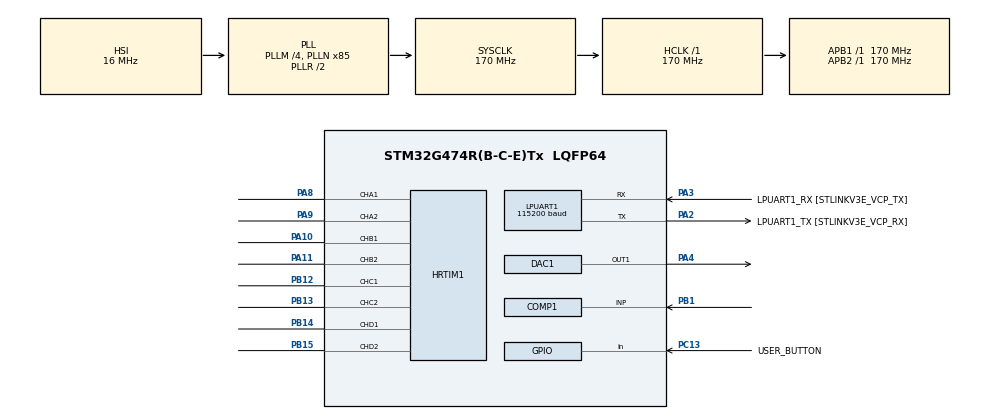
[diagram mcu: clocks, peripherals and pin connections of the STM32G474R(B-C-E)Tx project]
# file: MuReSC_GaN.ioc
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COMP1.Hysteresis=COMP_HYSTERESIS_10MV
COMP1.TriggerMode=COMP_TRIGGERMODE_IT_RISING_FALLING
HRTIM1.CompareUnit1-Output_TA1TA2=HRTIM_COMPAREUNIT_1
HRTIM1.CompareUnit1-Output_TB1TB2=__NULL
HRTIM1.CompareUnit1-Output_TC1TC2=HRTIM_COMPAREUNIT_1
HRTIM1.CompareUnit1-Output_TD1TD2=__NULL
HRTIM1.CompareUnit2-Output_TA1TA2=HRTIM_COMPAREUNIT_2
HRTIM1.CompareUnit2-Output_TB1TB2=HRTIM_COMPAREUNIT_2
HRTIM1.CompareUnit2-Output_TC1TC2=HRTIM_COMPAREUNIT_2
HRTIM1.CompareUnit2-Output_TD1TD2=HRTIM_COMPAREUNIT_2
HRTIM1.CompareValue1-Output_TA1TA2=4352/3
HRTIM1.CompareValue1-Output_TC1TC2=4352/10
HRTIM1.CompareValue2-Output_TA1TA2=4352*2/3
HRTIM1.CompareValue2-Output_TB1TB2=4352
HRTIM1.CompareValue2-Output_TC1TC2=4352*2/10
HRTIM1.CompareValue2-Output_TD1TD2=4352*3/20
HRTIM1.Deadtimeconfig-Output_TD1TD2=__NULL
HRTIM1.NumberResetSource1-Output_TA1TA2=1
HRTIM1.NumberResetSource1-Output_TB1TB2=1
HRTIM1.NumberResetSource1-Output_TC1TC2=1
HRTIM1.NumberResetSource1-Output_TD1TD2=1
HRTIM1.NumberResetSource2_TA=1
HRTIM1.NumberResetSource2_TB=1
HRTIM1.NumberResetSource2_TC=1
HRTIM1.NumberResetSource2_TD=1
HRTIM1.NumberSetSource1-Output_TA1TA2=1
HRTIM1.NumberSetSource1-Output_TB1TB2=1
HRTIM1.NumberSetSource1-Output_TC1TC2=1
HRTIM1.NumberSetSource1-Output_TD1TD2=1
HRTIM1.NumberSetSource2_TA=1
HRTIM1.NumberSetSource2_TB=1
HRTIM1.NumberSetSource2_TC=1
HRTIM1.NumberSetSource2_TD=1
HRTIM1.Periode_TA=4352
HRTIM1.Periode_TB=4352
HRTIM1.Periode_TC=4352
HRTIM1.Periode_TD=4352
HRTIM1.Polarity1-Output_TA1TA2=HRTIM_OUTPUTPOLARITY_LOW
HRTIM1.Polarity1-Output_TB1TB2=HRTIM_OUTPUTPOLARITY_LOW
HRTIM1.Polarity1-Output_TC1TC2=HRTIM_OUTPUTPOLARITY_LOW
HRTIM1.Polarity1-Output_TD1TD2=HRTIM_OUTPUTPOLARITY_LOW
HRTIM1.Polarity2-Output_TA1TA2=HRTIM_OUTPUTPOLARITY_HIGH
HRTIM1.Polarity2-Output_TB1TB2=HRTIM_OUTPUTPOLARITY_HIGH
HRTIM1.Polarity2-Output_TC1TC2=HRTIM_OUTPUTPOLARITY_HIGH
HRTIM1.Polarity2-Output_TD1TD2=HRTIM_OUTPUTPOLARITY_HIGH
HRTIM1.ResetOutput1_Source1-Output_TA1TA2=HRTIM_OUTPUTRESET_TIMCMP2
HRTIM1.ResetOutput1_Source1-Output_TB1TB2=HRTIM_OUTPUTRESET_TIMCMP2
HRTIM1.ResetOutput1_Source1-Output_TC1TC2=HRTIM_OUTPUTRESET_TIMCMP2
HRTIM1.ResetOutput1_Source1-Output_TD1TD2=HRTIM_OUTPUTRESET_TIMCMP2
HRTIM1.ResetOutput2_Source1-Output_TA1TA2=HRTIM_OUTPUTRESET_TIMCMP2
HRTIM1.ResetOutput2_Source1-Output_TB1TB2=HRTIM_OUTPUTRESET_TIMCMP2
HRTIM1.ResetOutput2_Source1-Output_TC1TC2=HRTIM_OUTPUTRESET_TIMCMP2
HRTIM1.ResetOutput2_Source1-Output_TD1TD2=HRTIM_OUTPUTRESET_TIMCMP2
HRTIM1.SetOutput1_Source1-Output_TA1TA2=HRTIM_OUTPUTSET_TIMCMP1
HRTIM1.SetOutput1_Source1-Output_TB1TB2=HRTIM_OUTPUTSET_TIMPER
HRTIM1.SetOutput1_Source1-Output_TC1TC2=HRTIM_OUTPUTSET_TIMCMP1
HRTIM1.SetOutput1_Source1-Output_TD1TD2=HRTIM_OUTPUTSET_TIMPER
HRTIM1.SetOutput2_Source1-Output_TA1TA2=HRTIM_OUTPUTSET_TIMCMP1
HRTIM1.SetOutput2_Source1-Output_TB1TB2=HRTIM_OUTPUTSET_TIMPER
HRTIM1.SetOutput2_Source1-Output_TC1TC2=HRTIM_OUTPUTSET_TIMCMP1
HRTIM1.SetOutput2_Source1-Output_TD1TD2=HRTIM_OUTPUTSET_TIMPER
LPUART1.BaudRate=115200
LPUART1.WordLength=UART_WORDLENGTH_8B
Mcu.Family=STM32G4
Mcu.Name=STM32G474R(B-C-E)Tx
Mcu.Package=LQFP64
NVIC.COMP1_2_3_IRQn=true\:0\:0\:false\:false\:true\:false\:true\:true
NVIC.LPUART1_IRQn=true\:0\:0\:false\:false\:true\:true\:true\:true
NVIC.PVD_PVM_IRQn=true\:0\:0\:false\:false\:true\:true\:true\:true
NVIC.PriorityGroup=NVIC_PRIORITYGROUP_4
PA10.GPIO_PuPd=GPIO_PULLUP
PA10.Mode=Output_TB1TB2
PA10.Signal=HRTIM1_CHB1
PA11.GPIO_PuPd=GPIO_PULLDOWN
PA11.Mode=Output_TB1TB2
PA11.Signal=HRTIM1_CHB2
PA13.GPIO_Label=T_SWDIO
PA13.Mode=Serial_Wire
PA13.Signal=SYS_JTMS-SWDIO
PA14.GPIO_Label=T_SWCLK
PA14.Mode=Serial_Wire
PA14.Signal=SYS_JTCK-SWCLK
PA2.GPIO_Label=LPUART1_TX [STLINKV3E_VCP_RX]
PA2.Mode=Asynchronous
PA2.Signal=LPUART1_TX
PA3.GPIO_Label=LPUART1_RX [STLINKV3E_VCP_TX]
PA3.Mode=Asynchronous
PA3.Signal=LPUART1_RX
PA4.Signal=COMP_DAC11_group
PA8.GPIO_PuPd=GPIO_PULLUP
PA8.Mode=Output_TA1TA2
PA8.Signal=HRTIM1_CHA1
PA9.GPIO_PuPd=GPIO_PULLDOWN
PA9.Mode=Output_TA1TA2
PA9.Signal=HRTIM1_CHA2
PB1.Mode=INP
PB1.Signal=COMP1_INP
PB12.GPIO_PuPd=GPIO_PULLUP
PB12.Mode=Output_TC1TC2
PB12.Signal=HRTIM1_CHC1
PB13.GPIO_PuPd=GPIO_PULLDOWN
PB13.Mode=Output_TC1TC2
PB13.Signal=HRTIM1_CHC2
PB14.GPIO_PuPd=GPIO_PULLUP
PB14.Mode=Output_TD1TD2
PB14.Signal=HRTIM1_CHD1
PB15.GPIO_PuPd=GPIO_PULLDOWN
PB15.Mode=Output_TD1TD2
PB15.Signal=HRTIM1_CHD2
PC13.GPIO_Label=USER_BUTTON
PC13.Signal=GPIO_Input
PC14-OSC32_IN.Mode=LSE-External-Oscillator
PC14-OSC32_IN.Signal=RCC_OSC32_IN
PC15-OSC32_OUT.Mode=LSE-External-Oscillator
PC15-OSC32_OUT.Signal=RCC_OSC32_OUT
PF0-OSC_IN.Mode=HSE-External-Oscillator
PF0-OSC_IN.Signal=RCC_OSC_IN
PF1-OSC_OUT.Mode=HSE-External-Oscillator
PF1-OSC_OUT.Signal=RCC_OSC_OUT
ProjectManager.HeapSize=0x200
ProjectManager.StackSize=0x400
ProjectManager.TargetToolchain=STM32CubeIDE
RCC.ADC12Freq_Value=170000000
RCC.ADC345Freq_Value=170000000
RCC.AHBFreq_Value=170000000
RCC.APB1Freq_Value=170000000
RCC.APB1TimFreq_Value=170000000
RCC.APB2Freq_Value=170000000
RCC.APB2TimFreq_Value=170000000
RCC.CortexFreq_Value=170000000
RCC.EXTERNAL_CLOCK_VALUE=12288000
RCC.HCLKFreq_Value=170000000
RCC.HSE_VALUE=24000000
RCC.HSI48_VALUE=48000000
RCC.HSI_VALUE=16000000
RCC.PLLM=RCC_PLLM_DIV4
RCC.PLLN=85
RCC.RTCClockSelection=RCC_RTCCLKSOURCE_LSE
RCC.SYSCLKFreq_VALUE=170000000
RCC.SYSCLKSource=RCC_SYSCLKSOURCE_PLLCLK
RCC.USBFreq_Value=170000000
RCC.VCOOutputFreq_Value=340000000
SH.COMP_DAC11_group.0=DAC1_OUT1,DAC_OUT1_ExtAndInt
VP_COMP1_VS_DAC1OUT1.Mode=INM_DAC1OUT1
VP_SYS_VS_DBSignals.Mode=DisableDeadBatterySignals
board=NUCLEO-G474RE

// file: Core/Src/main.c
/* USER CODE BEGIN Header */

/*
 * This file is part of the PCBs project (https://github.com/gremirarunico/PCBs).
 * Copyright (c) 2024 Marco Guerrini.
 *
 * This program is free software: you can redistribute it and/or modify
 * it under the terms of the GNU General Public License as published by
 * the Free Software Foundation, version 3.
 *
 * This program is distributed in the hope that it will be useful, but
 * WITHOUT ANY WARRANTY; without even the implied warranty of
 * MERCHANTABILITY or FITNESS FOR A PARTICULAR PURPOSE. See the GNU
 * General Public License for more details.
 *
 * You should have received a copy of the GNU General Public License
 * along with this program. If not, see <http://www.gnu.org/licenses/>.
 */

#include <stdio.h>
#include <stdbool.h>
#include <serial_parser.h>
#include "application.h"
/* USER CODE END Header */
#include "main.h"

COMP_HandleTypeDef hcomp1;

DAC_HandleTypeDef hdac1;

HRTIM_HandleTypeDef hhrtim1;

UART_HandleTypeDef hlpuart1;

void SystemClock_Config(void);
static void MX_GPIO_Init(void);
static void MX_LPUART1_UART_Init(void);
static void MX_HRTIM1_Init(void);
static void MX_DAC1_Init(void);
static void MX_COMP1_Init(void);

int main(void)
{

  /* MCU Configuration--------------------------------------------------------*/

  /* Reset of all peripherals, Initializes the Flash interface and the Systick. */
  HAL_Init();

  /* Configure the system clock */
  SystemClock_Config();

  /* Initialize all configured peripherals */
  MX_GPIO_Init();
  MX_LPUART1_UART_Init();
  MX_HRTIM1_Init();
  MX_DAC1_Init();
  MX_COMP1_Init();
  /* USER CODE BEGIN 2 */
  setup();

	while (1) {
		loop();
	}
	/* USER CODE BEGIN 3 */
	/* USER CODE END 3 */

  /* USER CODE END 2 */

  /* Infinite loop */

}

void SystemClock_Config(void)
{
  RCC_OscInitTypeDef RCC_OscInitStruct = {0};
  RCC_ClkInitTypeDef RCC_ClkInitStruct = {0};

  /** Configure the main internal regulator output voltage
  */
  HAL_PWREx_ControlVoltageScaling(PWR_REGULATOR_VOLTAGE_SCALE1_BOOST);

  /** Initializes the RCC Oscillators according to the specified parameters
  * in the RCC_OscInitTypeDef structure.
  */
  RCC_OscInitStruct.OscillatorType = RCC_OSCILLATORTYPE_HSI;
  RCC_OscInitStruct.HSIState = RCC_HSI_ON;
  RCC_OscInitStruct.HSICalibrationValue = RCC_HSICALIBRATION_DEFAULT;
  RCC_OscInitStruct.PLL.PLLState = RCC_PLL_ON;
  RCC_OscInitStruct.PLL.PLLSource = RCC_PLLSOURCE_HSI;
  RCC_OscInitStruct.PLL.PLLM = RCC_PLLM_DIV4;
  RCC_OscInitStruct.PLL.PLLN = 85;
  RCC_OscInitStruct.PLL.PLLP = RCC_PLLP_DIV2;
  RCC_OscInitStruct.PLL.PLLQ = RCC_PLLQ_DIV2;
  RCC_OscInitStruct.PLL.PLLR = RCC_PLLR_DIV2;
  if (HAL_RCC_OscConfig(&RCC_OscInitStruct) != HAL_OK)
  {
    Error_Handler();
  }

  /** Initializes the CPU, AHB and APB buses clocks
  */
  RCC_ClkInitStruct.ClockType = RCC_CLOCKTYPE_HCLK|RCC_CLOCKTYPE_SYSCLK
                              |RCC_CLOCKTYPE_PCLK1|RCC_CLOCKTYPE_PCLK2;
  RCC_ClkInitStruct.SYSCLKSource = RCC_SYSCLKSOURCE_PLLCLK;
  RCC_ClkInitStruct.AHBCLKDivider = RCC_SYSCLK_DIV1;
  RCC_ClkInitStruct.APB1CLKDivider = RCC_HCLK_DIV1;
  RCC_ClkInitStruct.APB2CLKDivider = RCC_HCLK_DIV1;

  if (HAL_RCC_ClockConfig(&RCC_ClkInitStruct, FLASH_LATENCY_4) != HAL_OK)
  {
    Error_Handler();
  }
}

static void MX_COMP1_Init(void)
{

  hcomp1.Instance = COMP1;
  hcomp1.Init.InputPlus = COMP_INPUT_PLUS_IO2;
  hcomp1.Init.InputMinus = COMP_INPUT_MINUS_DAC1_CH1;
  hcomp1.Init.OutputPol = COMP_OUTPUTPOL_NONINVERTED;
  hcomp1.Init.Hysteresis = COMP_HYSTERESIS_10MV;
  hcomp1.Init.BlankingSrce = COMP_BLANKINGSRC_NONE;
  hcomp1.Init.TriggerMode = COMP_TRIGGERMODE_IT_RISING_FALLING;
  if (HAL_COMP_Init(&hcomp1) != HAL_OK)
  {
    Error_Handler();
  }

}

static void MX_DAC1_Init(void)
{

  DAC_ChannelConfTypeDef sConfig = {0};

  /** DAC Initialization
  */
  hdac1.Instance = DAC1;
  if (HAL_DAC_Init(&hdac1) != HAL_OK)
  {
    Error_Handler();
  }

  /** DAC channel OUT1 config
  */
  sConfig.DAC_HighFrequency = DAC_HIGH_FREQUENCY_INTERFACE_MODE_AUTOMATIC;
  sConfig.DAC_DMADoubleDataMode = DISABLE;
  sConfig.DAC_SignedFormat = DISABLE;
  sConfig.DAC_SampleAndHold = DAC_SAMPLEANDHOLD_DISABLE;
  sConfig.DAC_Trigger = DAC_TRIGGER_NONE;
  sConfig.DAC_Trigger2 = DAC_TRIGGER_NONE;
  sConfig.DAC_OutputBuffer = DAC_OUTPUTBUFFER_ENABLE;
  sConfig.DAC_ConnectOnChipPeripheral = DAC_CHIPCONNECT_BOTH;
  sConfig.DAC_UserTrimming = DAC_TRIMMING_FACTORY;
  if (HAL_DAC_ConfigChannel(&hdac1, &sConfig, DAC_CHANNEL_1) != HAL_OK)
  {
    Error_Handler();
  }

}

static void MX_HRTIM1_Init(void)
{

  HRTIM_TimeBaseCfgTypeDef pTimeBaseCfg = {0};
  HRTIM_TimerCtlTypeDef pTimerCtl = {0};
  HRTIM_TimerCfgTypeDef pTimerCfg = {0};
  HRTIM_CompareCfgTypeDef pCompareCfg = {0};
  HRTIM_OutputCfgTypeDef pOutputCfg = {0};

  hhrtim1.Instance = HRTIM1;
  hhrtim1.Init.HRTIMInterruptResquests = HRTIM_IT_NONE;
  hhrtim1.Init.SyncOptions = HRTIM_SYNCOPTION_NONE;
  if (HAL_HRTIM_Init(&hhrtim1) != HAL_OK)
  {
    Error_Handler();
  }
  if (HAL_HRTIM_DLLCalibrationStart(&hhrtim1, HRTIM_CALIBRATIONRATE_3) != HAL_OK)
  {
    Error_Handler();
  }
  if (HAL_HRTIM_PollForDLLCalibration(&hhrtim1, 10) != HAL_OK)
  {
    Error_Handler();
  }
  pTimeBaseCfg.Period = 4352;
  pTimeBaseCfg.RepetitionCounter = 0x00;
  pTimeBaseCfg.PrescalerRatio = HRTIM_PRESCALERRATIO_MUL32;
  pTimeBaseCfg.Mode = HRTIM_MODE_CONTINUOUS;
  if (HAL_HRTIM_TimeBaseConfig(&hhrtim1, HRTIM_TIMERINDEX_TIMER_A, &pTimeBaseCfg) != HAL_OK)
  {
    Error_Handler();
  }
  pTimerCtl.UpDownMode = HRTIM_TIMERUPDOWNMODE_UP;
  pTimerCtl.TrigHalf = HRTIM_TIMERTRIGHALF_DISABLED;
  pTimerCtl.GreaterCMP1 = HRTIM_TIMERGTCMP1_EQUAL;
  pTimerCtl.DualChannelDacEnable = HRTIM_TIMER_DCDE_DISABLED;
  if (HAL_HRTIM_WaveformTimerControl(&hhrtim1, HRTIM_TIMERINDEX_TIMER_A, &pTimerCtl) != HAL_OK)
  {
    Error_Handler();
  }
  pTimerCfg.InterruptRequests = HRTIM_TIM_IT_NONE;
  pTimerCfg.DMARequests = HRTIM_TIM_DMA_NONE;
  pTimerCfg.DMASrcAddress = 0x0000;
  pTimerCfg.DMADstAddress = 0x0000;
  pTimerCfg.DMASize = 0x1;
  pTimerCfg.HalfModeEnable = HRTIM_HALFMODE_DISABLED;
  pTimerCfg.InterleavedMode = HRTIM_INTERLEAVED_MODE_DISABLED;
  pTimerCfg.StartOnSync = HRTIM_SYNCSTART_DISABLED;
  pTimerCfg.ResetOnSync = HRTIM_SYNCRESET_DISABLED;
  pTimerCfg.DACSynchro = HRTIM_DACSYNC_NONE;
  pTimerCfg.PreloadEnable = HRTIM_PRELOAD_DISABLED;
  pTimerCfg.UpdateGating = HRTIM_UPDATEGATING_INDEPENDENT;
  pTimerCfg.BurstMode = HRTIM_TIMERBURSTMODE_MAINTAINCLOCK;
  pTimerCfg.RepetitionUpdate = HRTIM_UPDATEONREPETITION_DISABLED;
  pTimerCfg.PushPull = HRTIM_TIMPUSHPULLMODE_DISABLED;
  pTimerCfg.FaultEnable = HRTIM_TIMFAULTENABLE_NONE;
  pTimerCfg.FaultLock = HRTIM_TIMFAULTLOCK_READWRITE;
  pTimerCfg.DeadTimeInsertion = HRTIM_TIMDEADTIMEINSERTION_DISABLED;
  pTimerCfg.DelayedProtectionMode = HRTIM_TIMER_A_B_C_DELAYEDPROTECTION_DISABLED;
  pTimerCfg.UpdateTrigger = HRTIM_TIMUPDATETRIGGER_NONE;
  pTimerCfg.ResetTrigger = HRTIM_TIMRESETTRIGGER_NONE;
  pTimerCfg.ResetUpdate = HRTIM_TIMUPDATEONRESET_DISABLED;
  pTimerCfg.ReSyncUpdate = HRTIM_TIMERESYNC_UPDATE_UNCONDITIONAL;
  if (HAL_HRTIM_WaveformTimerConfig(&hhrtim1, HRTIM_TIMERINDEX_TIMER_A, &pTimerCfg) != HAL_OK)
  {
    Error_Handler();
  }
  if (HAL_HRTIM_WaveformTimerConfig(&hhrtim1, HRTIM_TIMERINDEX_TIMER_B, &pTimerCfg) != HAL_OK)
  {
    Error_Handler();
  }
  if (HAL_HRTIM_WaveformTimerConfig(&hhrtim1, HRTIM_TIMERINDEX_TIMER_C, &pTimerCfg) != HAL_OK)
  {
    Error_Handler();
  }
  pTimerCfg.DelayedProtectionMode = HRTIM_TIMER_D_E_DELAYEDPROTECTION_DISABLED;
  if (HAL_HRTIM_WaveformTimerConfig(&hhrtim1, HRTIM_TIMERINDEX_TIMER_D, &pTimerCfg) != HAL_OK)
  {
    Error_Handler();
  }
  pCompareCfg.CompareValue = 4352/3;
  if (HAL_HRTIM_WaveformCompareConfig(&hhrtim1, HRTIM_TIMERINDEX_TIMER_A, HRTIM_COMPAREUNIT_1, &pCompareCfg) != HAL_OK)
  {
    Error_Handler();
  }
  pCompareCfg.CompareValue = 4352*2/3;
  pCompareCfg.AutoDelayedMode = HRTIM_AUTODELAYEDMODE_REGULAR;
  pCompareCfg.AutoDelayedTimeout = 0x0000;

  if (HAL_HRTIM_WaveformCompareConfig(&hhrtim1, HRTIM_TIMERINDEX_TIMER_A, HRTIM_COMPAREUNIT_2, &pCompareCfg) != HAL_OK)
  {
    Error_Handler();
  }
  pOutputCfg.Polarity = HRTIM_OUTPUTPOLARITY_LOW;
  pOutputCfg.SetSource = HRTIM_OUTPUTSET_TIMCMP1;
  pOutputCfg.ResetSource = HRTIM_OUTPUTRESET_TIMCMP2;
  pOutputCfg.IdleMode = HRTIM_OUTPUTIDLEMODE_NONE;
  pOutputCfg.IdleLevel = HRTIM_OUTPUTIDLELEVEL_INACTIVE;
  pOutputCfg.FaultLevel = HRTIM_OUTPUTFAULTLEVEL_NONE;
  pOutputCfg.ChopperModeEnable = HRTIM_OUTPUTCHOPPERMODE_DISABLED;
  pOutputCfg.BurstModeEntryDelayed = HRTIM_OUTPUTBURSTMODEENTRY_REGULAR;
  if (HAL_HRTIM_WaveformOutputConfig(&hhrtim1, HRTIM_TIMERINDEX_TIMER_A, HRTIM_OUTPUT_TA1, &pOutputCfg) != HAL_OK)
  {
    Error_Handler();
  }
  pOutputCfg.SetSource = HRTIM_OUTPUTSET_TIMPER;
  if (HAL_HRTIM_WaveformOutputConfig(&hhrtim1, HRTIM_TIMERINDEX_TIMER_B, HRTIM_OUTPUT_TB1, &pOutputCfg) != HAL_OK)
  {
    Error_Handler();
  }
  pOutputCfg.SetSource = HRTIM_OUTPUTSET_TIMCMP1;
  if (HAL_HRTIM_WaveformOutputConfig(&hhrtim1, HRTIM_TIMERINDEX_TIMER_C, HRTIM_OUTPUT_TC1, &pOutputCfg) != HAL_OK)
  {
    Error_Handler();
  }
  pOutputCfg.SetSource = HRTIM_OUTPUTSET_TIMPER;
  if (HAL_HRTIM_WaveformOutputConfig(&hhrtim1, HRTIM_TIMERINDEX_TIMER_D, HRTIM_OUTPUT_TD1, &pOutputCfg) != HAL_OK)
  {
    Error_Handler();
  }
  pOutputCfg.Polarity = HRTIM_OUTPUTPOLARITY_HIGH;
  pOutputCfg.SetSource = HRTIM_OUTPUTSET_TIMCMP1;
  if (HAL_HRTIM_WaveformOutputConfig(&hhrtim1, HRTIM_TIMERINDEX_TIMER_A, HRTIM_OUTPUT_TA2, &pOutputCfg) != HAL_OK)
  {
    Error_Handler();
  }
  pOutputCfg.SetSource = HRTIM_OUTPUTSET_TIMPER;
  if (HAL_HRTIM_WaveformOutputConfig(&hhrtim1, HRTIM_TIMERINDEX_TIMER_B, HRTIM_OUTPUT_TB2, &pOutputCfg) != HAL_OK)
  {
    Error_Handler();
  }
  pOutputCfg.SetSource = HRTIM_OUTPUTSET_TIMCMP1;
  if (HAL_HRTIM_WaveformOutputConfig(&hhrtim1, HRTIM_TIMERINDEX_TIMER_C, HRTIM_OUTPUT_TC2, &pOutputCfg) != HAL_OK)
  {
    Error_Handler();
  }
  pOutputCfg.SetSource = HRTIM_OUTPUTSET_TIMPER;
  if (HAL_HRTIM_WaveformOutputConfig(&hhrtim1, HRTIM_TIMERINDEX_TIMER_D, HRTIM_OUTPUT_TD2, &pOutputCfg) != HAL_OK)
  {
    Error_Handler();
  }
  if (HAL_HRTIM_TimeBaseConfig(&hhrtim1, HRTIM_TIMERINDEX_TIMER_B, &pTimeBaseCfg) != HAL_OK)
  {
    Error_Handler();
  }
  if (HAL_HRTIM_WaveformTimerControl(&hhrtim1, HRTIM_TIMERINDEX_TIMER_B, &pTimerCtl) != HAL_OK)
  {
    Error_Handler();
  }
  pCompareCfg.CompareValue = 4352;

  if (HAL_HRTIM_WaveformCompareConfig(&hhrtim1, HRTIM_TIMERINDEX_TIMER_B, HRTIM_COMPAREUNIT_2, &pCompareCfg) != HAL_OK)
  {
    Error_Handler();
  }
  if (HAL_HRTIM_TimeBaseConfig(&hhrtim1, HRTIM_TIMERINDEX_TIMER_C, &pTimeBaseCfg) != HAL_OK)
  {
    Error_Handler();
  }
  if (HAL_HRTIM_WaveformTimerControl(&hhrtim1, HRTIM_TIMERINDEX_TIMER_C, &pTimerCtl) != HAL_OK)
  {
    Error_Handler();
  }
  pCompareCfg.CompareValue = 4352/10;
  if (HAL_HRTIM_WaveformCompareConfig(&hhrtim1, HRTIM_TIMERINDEX_TIMER_C, HRTIM_COMPAREUNIT_1, &pCompareCfg) != HAL_OK)
  {
    Error_Handler();
  }
  pCompareCfg.CompareValue = 4352*2/10;

  if (HAL_HRTIM_WaveformCompareConfig(&hhrtim1, HRTIM_TIMERINDEX_TIMER_C, HRTIM_COMPAREUNIT_2, &pCompareCfg) != HAL_OK)
  {
    Error_Handler();
  }
  if (HAL_HRTIM_TimeBaseConfig(&hhrtim1, HRTIM_TIMERINDEX_TIMER_D, &pTimeBaseCfg) != HAL_OK)
  {
    Error_Handler();
  }
  if (HAL_HRTIM_WaveformTimerControl(&hhrtim1, HRTIM_TIMERINDEX_TIMER_D, &pTimerCtl) != HAL_OK)
  {
    Error_Handler();
  }
  pCompareCfg.CompareValue = 4352*3/20;

  if (HAL_HRTIM_WaveformCompareConfig(&hhrtim1, HRTIM_TIMERINDEX_TIMER_D, HRTIM_COMPAREUNIT_2, &pCompareCfg) != HAL_OK)
  {
    Error_Handler();
  }
  HAL_HRTIM_MspPostInit(&hhrtim1);

}

static void MX_LPUART1_UART_Init(void)
{

  hlpuart1.Instance = LPUART1;
  hlpuart1.Init.BaudRate = 115200;
  hlpuart1.Init.WordLength = UART_WORDLENGTH_8B;
  hlpuart1.Init.StopBits = UART_STOPBITS_1;
  hlpuart1.Init.Parity = UART_PARITY_NONE;
  hlpuart1.Init.Mode = UART_MODE_TX_RX;
  hlpuart1.Init.HwFlowCtl = UART_HWCONTROL_NONE;
  hlpuart1.Init.OneBitSampling = UART_ONE_BIT_SAMPLE_DISABLE;
  hlpuart1.Init.ClockPrescaler = UART_PRESCALER_DIV1;
  hlpuart1.AdvancedInit.AdvFeatureInit = UART_ADVFEATURE_NO_INIT;
  if (HAL_UART_Init(&hlpuart1) != HAL_OK)
  {
    Error_Handler();
  }
  if (HAL_UARTEx_SetTxFifoThreshold(&hlpuart1, UART_TXFIFO_THRESHOLD_1_8) != HAL_OK)
  {
    Error_Handler();
  }
  if (HAL_UARTEx_SetRxFifoThreshold(&hlpuart1, UART_RXFIFO_THRESHOLD_1_8) != HAL_OK)
  {
    Error_Handler();
  }
  if (HAL_UARTEx_DisableFifoMode(&hlpuart1) != HAL_OK)
  {
    Error_Handler();
  }

}

static void MX_GPIO_Init(void)
{
  GPIO_InitTypeDef GPIO_InitStruct = {0};

  /* GPIO Ports Clock Enable */
  __HAL_RCC_GPIOC_CLK_ENABLE();
  __HAL_RCC_GPIOF_CLK_ENABLE();
  __HAL_RCC_GPIOA_CLK_ENABLE();
  __HAL_RCC_GPIOB_CLK_ENABLE();

  /*Configure GPIO pin : USER_BUTTON_Pin */
  GPIO_InitStruct.Pin = USER_BUTTON_Pin;
  GPIO_InitStruct.Mode = GPIO_MODE_INPUT;
  GPIO_InitStruct.Pull = GPIO_NOPULL;
  HAL_GPIO_Init(USER_BUTTON_GPIO_Port, &GPIO_InitStruct);

}

/* USER CODE BEGIN 4 */

int __io_putchar(int ch) {
	/* Place your implementation of fputc here */
	/* e.g. write a character to the LPUART1 and Loop until the end of transmission */
	HAL_UART_Transmit(&hlpuart1, (uint8_t*) &ch, 1, 0xFFFF);

	return ch;
}

/* USER CODE END 4 */

void Error_Handler(void)
{
}
